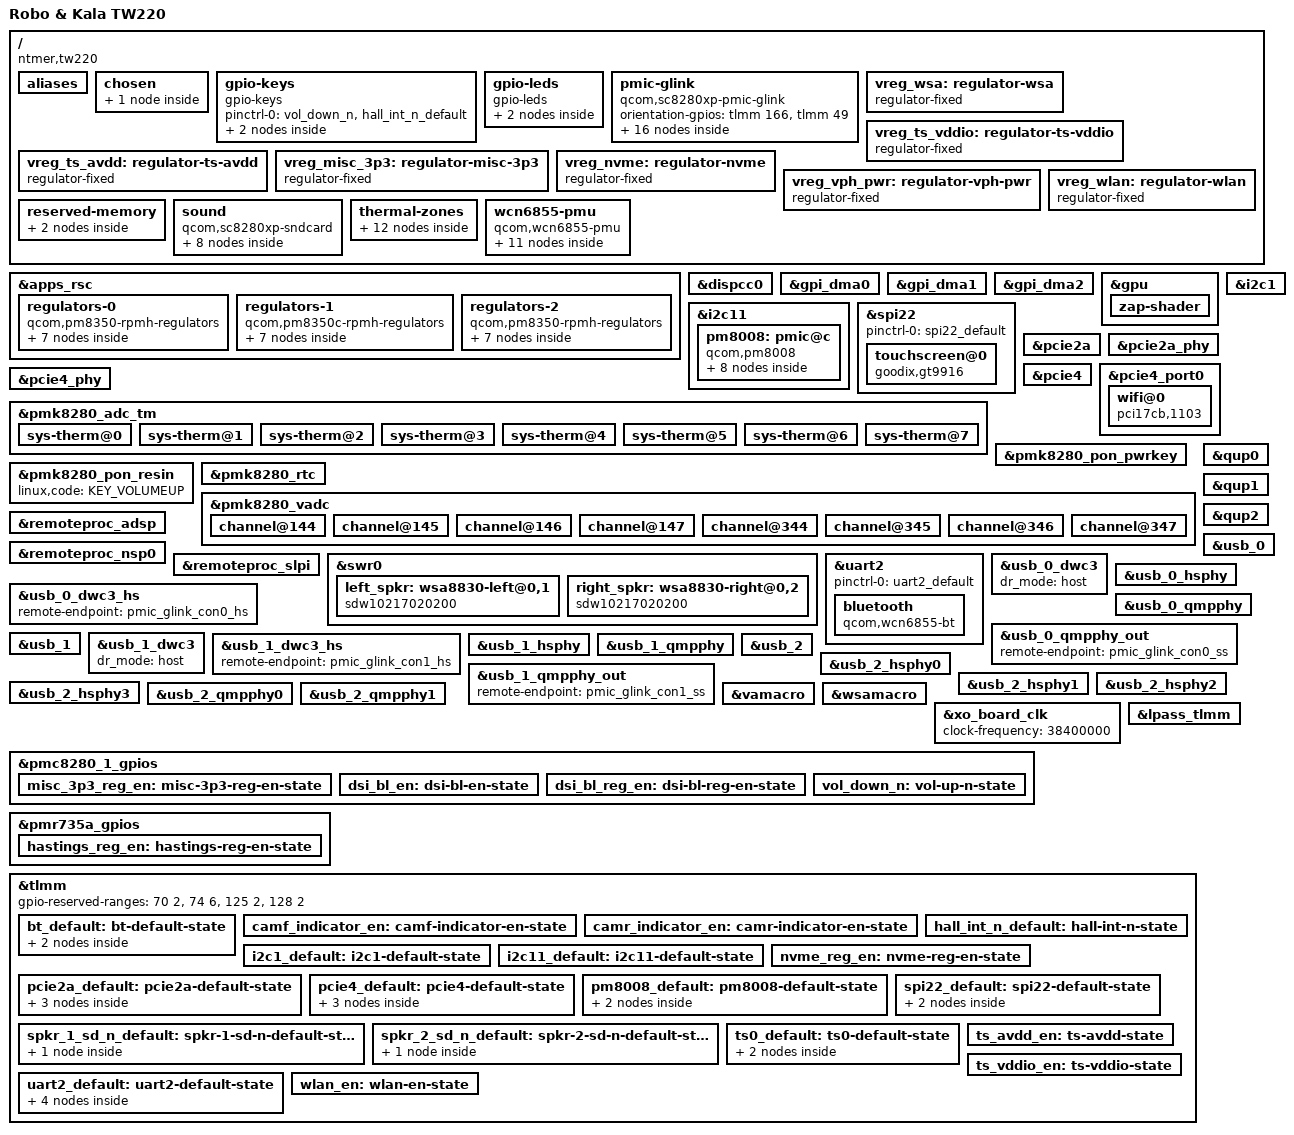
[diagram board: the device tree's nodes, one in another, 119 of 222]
// SPDX-License-Identifier: BSD-3-Clause
/*
 * Copyright (c) 2021, The Linux Foundation. All rights reserved.
 * Copyright (c) 2022, Linaro Limited
 *
 * Copyright (c) 2025, Hong Zhu <vanyang.smail.nju.edu.cn>
 * Copyright (c) 2025, Pengyu Luo <mitltlatltl@gmail.com>
 */

/dts-v1/;

#include <dt-bindings/gpio/gpio.h>
#include <dt-bindings/iio/qcom,spmi-adc7-pm8350.h>
#include <dt-bindings/input/gpio-keys.h>
#include <dt-bindings/input/input.h>
#include <dt-bindings/leds/common.h>
#include <dt-bindings/regulator/qcom,rpmh-regulator.h>
#include <dt-bindings/phy/phy.h>

#include "sc8280xp.dtsi"
#include "sc8280xp-pmics.dtsi"

/ {
	model = "Robo & Kala TW220";
	compatible = "ntmer,tw220", "qcom,sc8280xp";
	chassis-type = "tablet";

	aliases {
		serial0 = &uart2;
		i2c1 = &i2c1;
	};

	chosen {
		#address-cells = <2>;
		#size-cells = <2>;
		ranges;

		framebuffer0: framebuffer@c6200000 {
			compatible = "simple-framebuffer";
			reg = <0x0 0xc6200000 0x0 (2560*1600*4)>;
			width = <2560>;
			height = <1600>;
			stride = <(2560 * 4)>;
			format = "a8r8g8b8";
			clocks = <&dispcc0 DISP_CC_MDSS_MDP_CLK>;
		};
	};

	gpio-keys {
		compatible = "gpio-keys";

		pinctrl-0 = <&vol_down_n>, <&hall_int_n_default>;
		pinctrl-names = "default";

		key-vol-down {
			label = "Volume Down";
			gpios = <&pmc8280_1_gpios 6 GPIO_ACTIVE_LOW>;
			linux,code = <KEY_VOLUMEDOWN>;
			debounce-interval = <15>;
			linux,can-disable;
			wakeup-source;
		};

		switch-lid {
			label = "Lid Switch";
			gpios = <&tlmm 107 GPIO_ACTIVE_LOW>;
			linux,input-type = <EV_SW>;
			linux,code = <SW_LID>;
			wakeup-source;
			wakeup-event-action = <EV_ACT_DEASSERTED>;
		};
	};

	gpio-leds {
		compatible = "gpio-leds";

		pinctrl-names = "default";
		pinctrl-0 = <&camf_indicator_en>, <&camr_indicator_en>;

		flash_camf: led-front-camera-indicator {
			label = "white:front-camera-indicator";
			function = LED_FUNCTION_INDICATOR;
			color = <LED_COLOR_ID_WHITE>;
			gpios = <&tlmm 44 GPIO_ACTIVE_HIGH>;
			linux,default-trigger = "none";
			default-state = "off";
			/* Reuse as a panic indicator until we get a "camera on" trigger */
			panic-indicator;
		};

		flash_camr: led-rear-camera-indicator {
			label = "white:rear-camera-indicator";
			function = LED_FUNCTION_INDICATOR;
			color = <LED_COLOR_ID_WHITE>;
			gpios = <&tlmm 43 GPIO_ACTIVE_HIGH>;
			linux,default-trigger = "none";
			default-state = "off";
			/* Reuse as a panic indicator until we get a "camera on" trigger */
			panic-indicator;
		};
	};

	pmic-glink {
		compatible = "qcom,sc8280xp-pmic-glink", "qcom,pmic-glink";

		#address-cells = <1>;
		#size-cells = <0>;
		orientation-gpios = <&tlmm 166 GPIO_ACTIVE_HIGH>,
				    <&tlmm 49 GPIO_ACTIVE_HIGH>;

		connector@0 {
			compatible = "usb-c-connector";
			reg = <0>;
			power-role = "dual";
			data-role = "dual";

			ports {
				#address-cells = <1>;
				#size-cells = <0>;

				port@0 {
					reg = <0>;

					pmic_glink_con0_hs: endpoint {
						remote-endpoint = <&usb_0_dwc3_hs>;
					};
				};

				port@1 {
					reg = <1>;

					pmic_glink_con0_ss: endpoint {
						remote-endpoint = <&usb_0_qmpphy_out>;
					};
				};

				port@2 {
					reg = <2>;

					pmic_glink_con0_sbu: endpoint {
					};
				};
			};
		};

		connector@1 {
			compatible = "usb-c-connector";
			reg = <1>;
			power-role = "dual";
			data-role = "dual";

			ports {
				#address-cells = <1>;
				#size-cells = <0>;
				port@0 {
					reg = <0>;

					pmic_glink_con1_hs: endpoint {
						remote-endpoint = <&usb_1_dwc3_hs>;
					};
				};

				port@1 {
					reg = <1>;

					pmic_glink_con1_ss: endpoint {
						remote-endpoint = <&usb_1_qmpphy_out>;
					};
				};

				port@2 {
					reg = <2>;

					pmic_glink_con1_sbu: endpoint {
					};
				};
			};
		};
	};

	vreg_wsa: regulator-wsa {
		compatible = "regulator-fixed";

		regulator-name = "vreg_wsa";
		gpio = <&tlmm 28 GPIO_ACTIVE_HIGH>;
		regulator-min-microvolt = <3600000>;
		regulator-max-microvolt = <3600000>;
		enable-active-high;

		regulator-always-on;
		regulator-boot-on;
	};

	vreg_ts_vddio: regulator-ts-vddio {
		compatible = "regulator-fixed";

		regulator-name = "vreg_ts_vddio";
		regulator-min-microvolt = <1800000>;
		regulator-max-microvolt = <1800000>;

		gpio = <&tlmm 90 GPIO_ACTIVE_HIGH>;
		enable-active-high;

		pinctrl-0 = <&ts_vddio_en>;
		pinctrl-names = "default";
	};

	vreg_ts_avdd: regulator-ts-avdd {
		compatible = "regulator-fixed";

		regulator-name = "vreg_ts_avdd";
		regulator-min-microvolt = <3300000>;
		regulator-max-microvolt = <3300000>;

		gpio = <&tlmm 56 GPIO_ACTIVE_HIGH>;
		enable-active-high;

		pinctrl-0 = <&ts_avdd_en>;
		pinctrl-names = "default";
	};

	vreg_misc_3p3: regulator-misc-3p3 {
		compatible = "regulator-fixed";

		regulator-name = "VCC3B";
		regulator-min-microvolt = <3300000>;
		regulator-max-microvolt = <3300000>;

		gpio = <&pmc8280_1_gpios 1 GPIO_ACTIVE_HIGH>;
		enable-active-high;

		pinctrl-0 = <&misc_3p3_reg_en>;
		pinctrl-names = "default";

		regulator-boot-on;
		regulator-always-on;
	};

	vreg_nvme: regulator-nvme {
		compatible = "regulator-fixed";

		regulator-name = "VCC3_SSD";
		regulator-min-microvolt = <3300000>;
		regulator-max-microvolt = <3300000>;

		gpio = <&tlmm 135 GPIO_ACTIVE_HIGH>;
		enable-active-high;

		pinctrl-0 = <&nvme_reg_en>;
		pinctrl-names = "default";

		regulator-boot-on;
	};

	vreg_vph_pwr: regulator-vph-pwr {
		compatible = "regulator-fixed";

		regulator-name = "VPH_VCC3R9";
		regulator-min-microvolt = <3900000>;
		regulator-max-microvolt = <3900000>;

		regulator-always-on;
	};

	vreg_wlan: regulator-wlan {
		compatible = "regulator-fixed";

		regulator-name = "VCC_WLAN_3R9";
		regulator-min-microvolt = <3900000>;
		regulator-max-microvolt = <3900000>;

		gpio = <&pmr735a_gpios 1 GPIO_ACTIVE_HIGH>;
		enable-active-high;

		pinctrl-0 = <&hastings_reg_en>;
		pinctrl-names = "default";

		regulator-boot-on;
	};

	reserved-memory {
		gpu_mem: gpu-mem@8bf00000 {
			reg = <0 0x8bf00000 0 0x2000>;
			no-map;
		};

		linux,cma {
			compatible = "shared-dma-pool";
			size = <0x0 0x8000000>;
			reusable;
			linux,cma-default;
		};
	};

	sound {
		compatible = "qcom,sc8280xp-sndcard";
		model = "SC8280XP-NTMER-TW220";
		audio-routing = "SpkrLeft IN", "WSA_SPK1 OUT",
				"SpkrRight IN", "WSA_SPK2 OUT";

		wsa-dai-link {
			link-name = "WSA Playback";

			cpu {
				sound-dai = <&q6apmbedai WSA_CODEC_DMA_RX_0>;
			};

			codec {
				sound-dai = <&left_spkr>, <&right_spkr>, <&swr0 0>, <&wsamacro 0>;
			};

			platform {
				sound-dai = <&q6apm>;
			};
		};

		va-dai-link {
			link-name = "VA Capture";
			cpu {
				sound-dai = <&q6apmbedai VA_CODEC_DMA_TX_0>;
			};

			codec {
				sound-dai = <&vamacro 0>;
			};

			platform {
				sound-dai = <&q6apm>;
			};
		};
	};

	thermal-zones {
		pm8008-thermal {
			polling-delay-passive = <100>;
			polling-delay = <0>;

			thermal-sensors = <&pm8008>;

			trips {
				trip0 {
					temperature = <95000>;
					hysteresis = <0>;
					type = "passive";
				};

				trip1 {
					temperature = <115000>;
					hysteresis = <0>;
					type = "critical";
				};
			};
		};

		skin-temp-thermal {
			polling-delay-passive = <250>;

			thermal-sensors = <&pmk8280_adc_tm 5>;

			trips {
				skin_temp_alert0: trip-point0 {
					temperature = <55000>;
					hysteresis = <1000>;
					type = "passive";
				};

				skin_temp_alert1: trip-point1 {
					temperature = <58000>;
					hysteresis = <1000>;
					type = "passive";
				};

				skin-temp-crit {
					temperature = <73000>;
					hysteresis = <1000>;
					type = "critical";
				};
			};

			cooling-maps {
				map0 {
					trip = <&skin_temp_alert0>;
					cooling-device = <&cpu4 THERMAL_NO_LIMIT THERMAL_NO_LIMIT>,
					<&cpu5 THERMAL_NO_LIMIT THERMAL_NO_LIMIT>,
					<&cpu6 THERMAL_NO_LIMIT THERMAL_NO_LIMIT>,
					<&cpu7 THERMAL_NO_LIMIT THERMAL_NO_LIMIT>;
				};

				map1 {
					trip = <&skin_temp_alert1>;
					cooling-device = <&cpu4 THERMAL_NO_LIMIT THERMAL_NO_LIMIT>,
					<&cpu5 THERMAL_NO_LIMIT THERMAL_NO_LIMIT>,
					<&cpu6 THERMAL_NO_LIMIT THERMAL_NO_LIMIT>,
					<&cpu7 THERMAL_NO_LIMIT THERMAL_NO_LIMIT>;
				};
			};
		};
	};

	wcn6855-pmu {
		compatible = "qcom,wcn6855-pmu";

		pinctrl-names = "default";
		pinctrl-0 = <&bt_default>, <&wlan_en>;

		wlan-enable-gpios = <&tlmm 134 GPIO_ACTIVE_HIGH>;
		bt-enable-gpios = <&tlmm 133 GPIO_ACTIVE_HIGH>;
		swctrl-gpios = <&tlmm 132 GPIO_ACTIVE_HIGH>;

		vddio-supply = <&vreg_s10b>;
		vddaon-supply = <&vreg_s12b>;
		vddpmu-supply = <&vreg_s12b>;
		vddpmumx-supply = <&vreg_s12b>;
		vddpmucx-supply = <&vreg_s12b>;
		vddrfa0p95-supply = <&vreg_s12b>;
		vddrfa1p3-supply = <&vreg_s11b>;
		vddrfa1p9-supply = <&vreg_s1c>;
		vddpcie1p3-supply = <&vreg_s11b>;
		vddpcie1p9-supply = <&vreg_s1c>;

		regulators {
			vreg_pmu_rfa_cmn_0p8: ldo0 {
				regulator-name = "vreg_pmu_rfa_cmn_0p8";
			};

			vreg_pmu_aon_0p8: ldo1 {
				regulator-name = "vreg_pmu_aon_0p8";
			};

			vreg_pmu_wlcx_0p8: ldo2 {
				regulator-name = "vreg_pmu_wlcx_0p8";
			};

			vreg_pmu_wlmx_0p8: ldo3 {
				regulator-name = "vreg_pmu_wlmx_0p8";
			};

			vreg_pmu_btcmx_0p8: ldo4 {
				regulator-name = "vreg_pmu_btcmx_0p8";
			};

			vreg_pmu_pcie_1p8: ldo5 {
				regulator-name = "vreg_pmu_pcie_1p8";
			};

			vreg_pmu_pcie_0p9: ldo6 {
				regulator-name = "vreg_pmu_pcie_0p9";
			};

			vreg_pmu_rfa_0p8: ldo7 {
				regulator-name = "vreg_pmu_rfa_0p8";
			};

			vreg_pmu_rfa_1p2: ldo8 {
				regulator-name = "vreg_pmu_rfa_1p2";
			};

			vreg_pmu_rfa_1p7: ldo9 {
				regulator-name = "vreg_pmu_rfa_1p7";
			};
		};
	};
};

&apps_rsc {
	regulators-0 {
		compatible = "qcom,pm8350-rpmh-regulators";
		qcom,pmic-id = "b";

		vdd-l1-l4-supply = <&vreg_s12b>;
		vdd-l2-l7-supply = <&vreg_bob>;
		vdd-l3-l5-supply = <&vreg_s11b>;
		vdd-l6-l9-l10-supply = <&vreg_s12b>;
		vdd-l8-supply = <&vreg_s12b>;

		vreg_s10b: smps10 {
			regulator-name = "vreg_s10b";
			regulator-min-microvolt = <1800000>;
			regulator-max-microvolt = <1800000>;
			regulator-initial-mode = <RPMH_REGULATOR_MODE_HPM>;
			regulator-always-on;
		};

		vreg_s11b: smps11 {
			regulator-name = "vreg_s11b";
			regulator-min-microvolt = <1272000>;
			regulator-max-microvolt = <1272000>;
			regulator-initial-mode = <RPMH_REGULATOR_MODE_HPM>;
		};

		vreg_s12b: smps12 {
			regulator-name = "vreg_s12b";
			regulator-min-microvolt = <984000>;
			regulator-max-microvolt = <984000>;
			regulator-initial-mode = <RPMH_REGULATOR_MODE_HPM>;
		};

		vreg_l1b: ldo1 {
			regulator-name = "vreg_l1b";
			regulator-min-microvolt = <912000>;
			regulator-max-microvolt = <912000>;
			regulator-initial-mode = <RPMH_REGULATOR_MODE_HPM>;
			regulator-allow-set-load;
			regulator-allowed-modes = <RPMH_REGULATOR_MODE_LPM
			RPMH_REGULATOR_MODE_HPM>;
		};

		vreg_l3b: ldo3 {
			regulator-name = "vreg_l3b";
			regulator-min-microvolt = <1200000>;
			regulator-max-microvolt = <1200000>;
			regulator-initial-mode = <RPMH_REGULATOR_MODE_HPM>;
			regulator-boot-on;
		};

		vreg_l4b: ldo4 {
			regulator-name = "vreg_l4b";
			regulator-min-microvolt = <912000>;
			regulator-max-microvolt = <912000>;
			regulator-initial-mode = <RPMH_REGULATOR_MODE_HPM>;
			regulator-allow-set-load;
			regulator-allowed-modes = <RPMH_REGULATOR_MODE_LPM
			RPMH_REGULATOR_MODE_HPM>;
		};

		vreg_l6b: ldo6 {
			regulator-name = "vreg_l6b";
			regulator-min-microvolt = <880000>;
			regulator-max-microvolt = <880000>;
			regulator-initial-mode = <RPMH_REGULATOR_MODE_HPM>;
			regulator-boot-on;
		};
	};

	regulators-1 {
		compatible = "qcom,pm8350c-rpmh-regulators";
		qcom,pmic-id = "c";

		vdd-bob-supply = <&vreg_vph_pwr>;
		vdd-l1-l12-supply = <&vreg_s1c>;
		vdd-l2-l8-supply = <&vreg_s1c>;
		vdd-l3-l4-l5-l7-l13-supply = <&vreg_bob>;
		vdd-l6-l9-l11-supply = <&vreg_bob>;
		vdd-l10-supply = <&vreg_s11b>;

		vreg_s1c: smps1 {
			regulator-name = "vreg_s1c";
			regulator-min-microvolt = <1880000>;
			regulator-max-microvolt = <1900000>;
			regulator-initial-mode = <RPMH_REGULATOR_MODE_HPM>;
			regulator-always-on;
		};

		vreg_l1c: ldo1 {
			regulator-name = "vreg_l1c";
			regulator-min-microvolt = <1800000>;
			regulator-max-microvolt = <1800000>;
			regulator-initial-mode = <RPMH_REGULATOR_MODE_HPM>;
			regulator-allow-set-load;
			regulator-allowed-modes = <RPMH_REGULATOR_MODE_LPM
						   RPMH_REGULATOR_MODE_HPM>;
		};

		vreg_l2c: ldo2 {
			regulator-name = "vreg_l2c";
			regulator-min-microvolt = <1800000>;
			regulator-max-microvolt = <1800000>;
			regulator-initial-mode = <RPMH_REGULATOR_MODE_HPM>;
			regulator-allow-set-load;
			regulator-allowed-modes = <RPMH_REGULATOR_MODE_HPM>;
			regulator-always-on;
			regulator-boot-on;
		};

		vreg_l8c: ldo8 {
			regulator-name = "vreg_l8c";
			regulator-min-microvolt = <1800000>;
			regulator-max-microvolt = <1800000>;
			regulator-initial-mode = <RPMH_REGULATOR_MODE_HPM>;
			regulator-allow-set-load;
			regulator-allowed-modes = <RPMH_REGULATOR_MODE_LPM
						   RPMH_REGULATOR_MODE_HPM>;
		};

		vreg_l12c: ldo12 {
			regulator-name = "vreg_l12c";
			regulator-min-microvolt = <1800000>;
			regulator-max-microvolt = <1800000>;
			regulator-initial-mode = <RPMH_REGULATOR_MODE_HPM>;
		};

		vreg_l13c: ldo13 {
			regulator-name = "vreg_l13c";
			regulator-min-microvolt = <3072000>;
			regulator-max-microvolt = <3072000>;
			regulator-initial-mode = <RPMH_REGULATOR_MODE_HPM>;
			regulator-allow-set-load;
			regulator-allowed-modes = <RPMH_REGULATOR_MODE_LPM
						   RPMH_REGULATOR_MODE_HPM>;
		};

		vreg_bob: bob {
			regulator-name = "vreg_bob";
			regulator-min-microvolt = <3008000>;
			regulator-max-microvolt = <3960000>;
			regulator-initial-mode = <RPMH_REGULATOR_MODE_AUTO>;
			regulator-always-on;
		};
	};

	regulators-2 {
		compatible = "qcom,pm8350-rpmh-regulators";
		qcom,pmic-id = "d";

		vdd-l1-l4-supply = <&vreg_s11b>;
		vdd-l2-l7-supply = <&vreg_bob>;
		vdd-l3-l5-supply = <&vreg_s11b>;
		vdd-l6-l9-l10-supply = <&vreg_s12b>;
		vdd-l8-supply = <&vreg_s12b>;

		vreg_l2d: ldo2 {
			regulator-name = "vreg_l2d";
			regulator-min-microvolt = <3072000>;
			regulator-max-microvolt = <3072000>;
			regulator-initial-mode = <RPMH_REGULATOR_MODE_HPM>;
			regulator-allow-set-load;
			regulator-allowed-modes = <RPMH_REGULATOR_MODE_LPM
						   RPMH_REGULATOR_MODE_HPM>;
		};

		vreg_l4d: ldo4 {
			regulator-name = "vreg_l4d";
			regulator-min-microvolt = <1200000>;
			regulator-max-microvolt = <1200000>;
			regulator-initial-mode = <RPMH_REGULATOR_MODE_HPM>;
			regulator-allow-set-load;
			regulator-allowed-modes = <RPMH_REGULATOR_MODE_LPM
						   RPMH_REGULATOR_MODE_HPM>;
		};

		vreg_l6d: ldo6 {
			regulator-name = "vreg_l6d";
			regulator-min-microvolt = <880000>;
			regulator-max-microvolt = <880000>;
			regulator-initial-mode = <RPMH_REGULATOR_MODE_HPM>;
			regulator-allow-set-load;
			regulator-allowed-modes = <RPMH_REGULATOR_MODE_LPM
						   RPMH_REGULATOR_MODE_HPM>;
		};

		vreg_l7d: ldo7 {
			regulator-name = "vreg_l7d";
			regulator-min-microvolt = <3072000>;
			regulator-max-microvolt = <3072000>;
			regulator-initial-mode = <RPMH_REGULATOR_MODE_HPM>;
			regulator-allow-set-load;
			regulator-allowed-modes = <RPMH_REGULATOR_MODE_LPM
						   RPMH_REGULATOR_MODE_HPM>;
		};

		vreg_l8d: ldo8 {
			regulator-name = "vreg_l8d";
			regulator-min-microvolt = <912000>;
			regulator-max-microvolt = <912000>;
			regulator-initial-mode = <RPMH_REGULATOR_MODE_HPM>;
			regulator-allow-set-load;
			regulator-allowed-modes = <RPMH_REGULATOR_MODE_LPM
						   RPMH_REGULATOR_MODE_HPM>;
		};

		vreg_l9d: ldo9 {
			regulator-name = "vreg_l9d";
			regulator-min-microvolt = <912000>;
			regulator-max-microvolt = <912000>;
			regulator-initial-mode = <RPMH_REGULATOR_MODE_HPM>;
			regulator-allow-set-load;
			regulator-allowed-modes = <RPMH_REGULATOR_MODE_LPM
						   RPMH_REGULATOR_MODE_HPM>;
		};

		vreg_l10d: ldo10 {
			regulator-name = "vreg_l10d";
			regulator-min-microvolt = <912000>;
			regulator-max-microvolt = <912000>;
			regulator-initial-mode = <RPMH_REGULATOR_MODE_HPM>;
			regulator-allow-set-load;
			regulator-boot-on;
			regulator-always-on;
			regulator-allowed-modes = <RPMH_REGULATOR_MODE_LPM
						   RPMH_REGULATOR_MODE_HPM>;
		};
	};
};

/*
 * cci0_i2c1
 * sda: gpio115, scl: gpio116
 *
 * CAMI ov9234 @36 @48
 *
 * power on sequence
 * gpio7 out low
 * l3q 1p8
 * l6q 2p8
 * l2q 1p2
 * gpio7 out high
 * msleep 5
 * cam_cc_mclk4_clk 2.4MHz (gpio6)
 */

/*
 * cci2_i2c1
 * sda: gpio12, scl: gpio13
 *
 * CAMF gc5035 @37
 *
 * power on sequence
 * gpio15 out low
 * l3q 1p8
 * msleep 1
 * l2q 1p2
 * msleep 1
 * l5q 2p8
 * gpio15 out high
 * gpio67 out high
 * msleep 10
 * cam_cc_mclk3_clk 2.4MHz (gpio17)
 */

/*
 * cci1_i2c0
 * sda: gpio10, scl: gpio11
 *
 * CAMR ov13b10 @0c
 *
 * power on sequence
 * gpio66 out low
 * l1q 1p2
 * l7q 2p8
 * l3q 1p8
 * gpio59 out high
 * gpio66 out high
 * msleep 5
 * cam_cc_mclk2_clk 2.4MHz (gpio16/gpio119/gpio120?)
 */

&dispcc0 {
	status = "okay";
};

&gpi_dma0 {
	status = "okay";
};

&gpi_dma1 {
	status = "okay";
};

&gpi_dma2 {
	status = "okay";
};

&gpu {
	status = "okay";

	zap-shader {
		memory-region = <&gpu_mem>;
		firmware-name = "qcom/sc8280xp/Ntmer/tw220/qcdxkmsuc8280.mbn";
	};
};

&i2c1 {
	clock-frequency = <400000>;

	pinctrl-0 = <&i2c1_default>;
	pinctrl-names = "default";

	status = "okay";

	/*
	 * cps4035 @30 @31
	 * gpio73, 87, 154
	 */
};

&i2c11 {
	clock-frequency = <400000>;

	pinctrl-names = "default";
	pinctrl-0 = <&i2c11_default>;

	status = "okay";

	pm8008: pmic@c {
		compatible = "qcom,pm8008";
		reg = <0xc>;

		interrupts-extended = <&tlmm 41 IRQ_TYPE_EDGE_RISING>;
		reset-gpios = <&tlmm 42 GPIO_ACTIVE_LOW>;

		vdd-l1-l2-supply = <&vreg_s11b>;
		vdd-l3-l4-supply = <&vreg_bob>;
		vdd-l5-supply = <&vreg_bob>;
		vdd-l6-supply = <&vreg_bob>;
		vdd-l7-supply = <&vreg_bob>;

		pinctrl-names = "default";
		pinctrl-0 = <&pm8008_default>;

		gpio-controller;
		#gpio-cells = <2>;
		gpio-ranges = <&pm8008 0 0 2>;

		interrupt-controller;
		#interrupt-cells = <2>;

		#thermal-sensor-cells = <0>;

		regulators {
			vreg_l1q: ldo1 {
				regulator-name = "vreg_l1q";
				regulator-min-microvolt = <1200000>;
				regulator-max-microvolt = <1200000>;
			};

			vreg_l2q: ldo2 {
				regulator-name = "vreg_l2q";
				regulator-min-microvolt = <1200000>;
				regulator-max-microvolt = <1200000>;
			};

			vreg_l3q: ldo3 {
				regulator-name = "vreg_l3q";
				regulator-min-microvolt = <1800000>;
				regulator-max-microvolt = <1800000>;
			};

			vreg_l4q: ldo4 {
				regulator-name = "vreg_l4q";
				regulator-min-microvolt = <1800000>;
				regulator-max-microvolt = <1800000>;
			};

			vreg_l5q: ldo5 {
				regulator-name = "vreg_l5q";
				regulator-min-microvolt = <2800000>;
				regulator-max-microvolt = <2800000>;
			};

			vreg_l6q: ldo6 {
				regulator-name = "vreg_l6q";
				regulator-min-microvolt = <2800000>;
				regulator-max-microvolt = <2800000>;
			};

			vreg_l7q: ldo7 {
				regulator-name = "vreg_l7q";
				regulator-min-microvolt = <2800000>;
				regulator-max-microvolt = <2800000>;
			};
		};
	};
};

&spi22 {
	status = "okay";
	pinctrl-0 = <&spi22_default>;
	pinctrl-names = "default";

	touchscreen@0 {
		/*
		 * The ACPI device ID is GXTS7986, its exact suffix is unknown.
		 * The Windows driver suggests it is a GTBerlinB variant and
		 * communicates via HID over SPI, which aligns with the Linux
		 * driver `drivers/hid/hid-goodix-spi.c`.
		 *
		 * However, the HID descriptor read from the device appears
		 * garbled, preventing proper probe with the HID driver. In
		 * contrast, the driver at
		 * `drivers/input/touchscreen/goodix_berlin_spi.c` shares many
		 * similarities and functions correctly with this hardware.
		 *
		 * Therefore, we choose to use the goodix_berlin_spi driver
		 * instead.
		 */
		compatible = "goodix,gt9916";
		reg = <0>;

		interrupts-extended = <&tlmm 175 IRQ_TYPE_LEVEL_LOW>;
		reset-gpios = <&tlmm 99 GPIO_ACTIVE_LOW>;
		vddio-supply = <&vreg_ts_vddio>;
		avdd-supply = <&vreg_ts_avdd>;

		spi-max-frequency = <3000000>;

		touchscreen-size-x = <2560>;
		touchscreen-size-y = <1600>;

		pinctrl-0 = <&ts0_default>;
		pinctrl-names = "default";
	};
};

/*
 * mdss0_dsi display:
 *
 * reset gpio109
 *
 * power on seq:
 * ldo 3b: 1.2v dsi
 * ldo 6b: 0.88v dsi_phy
 *
 * panel:
 * ldo 2b: 1.8v vddio
 * gpio55 out high
 * msleep 15
 * gpio25 out high
 * msleep 5
 *
 * backlight:
 * dsi_bl_reg_en: gpio9
 * msleep 5
 * dsi_bl_en: gpio8
 *
 * power off sequence
 * dis_off:
 * ldo 3b
 * ldo 6b
 * ldo 2b
 *
 * bl_off:
 * dsi_bl_en: gpio8
 * msleep 5
 * dsi_bl_reg_en: gpio9
 * msleep 5
 *
 * panel_off:
 * gpio25: out low
 * msleep 5
 * gpio55: out low
 * msleep 5
 */

&pcie2a {
	perst-gpios = <&tlmm 143 GPIO_ACTIVE_LOW>;
	wake-gpios = <&tlmm 145 GPIO_ACTIVE_LOW>;

	vddpe-3v3-supply = <&vreg_nvme>;

	pinctrl-0 = <&pcie2a_default>;
	pinctrl-names = "default";

	status = "okay";
};

&pcie2a_phy {
	vdda-phy-supply = <&vreg_l6d>;
	vdda-pll-supply = <&vreg_l4d>;

	status = "okay";
};

&pcie4 {
	max-link-speed = <2>;

	perst-gpios = <&tlmm 141 GPIO_ACTIVE_LOW>;
	wake-gpios = <&tlmm 139 GPIO_ACTIVE_LOW>;

	vddpe-3v3-supply = <&vreg_wlan>;

	pinctrl-0 = <&pcie4_default>;
	pinctrl-names = "default";

	status = "okay";
};

&pcie4_port0 {
	wifi@0 {
		compatible = "pci17cb,1103";
		reg = <0x10000 0x0 0x0 0x0 0x0>;

		vddrfacmn-supply = <&vreg_pmu_rfa_cmn_0p8>;
		vddaon-supply = <&vreg_pmu_aon_0p8>;
		vddwlcx-supply = <&vreg_pmu_wlcx_0p8>;
		vddwlmx-supply = <&vreg_pmu_wlmx_0p8>;
		vddpcie1p8-supply = <&vreg_pmu_pcie_1p8>;
		vddpcie0p9-supply = <&vreg_pmu_pcie_0p9>;
		vddrfa0p8-supply = <&vreg_pmu_rfa_0p8>;
		vddrfa1p2-supply = <&vreg_pmu_rfa_1p2>;
		vddrfa1p8-supply = <&vreg_pmu_rfa_1p7>;

		/*
		 * bus=pci,vendor=17cb,device=1103,subsystem-vendor=17cb,
		 * subsystem-device=0108,qmi-chip-id=18,qmi-board-id=255
		 *
		 * Regenerate board file, x13s one works well
		 */
	};
};

&pcie4_phy {
	vdda-phy-supply = <&vreg_l6d>;
	vdda-pll-supply = <&vreg_l4d>;

	status = "okay";
};

&pmk8280_adc_tm {
	status = "okay";

	sys-therm@0 {
		reg = <0>;
		io-channels = <&pmk8280_vadc PM8350_ADC7_AMUX_THM1_100K_PU(1)>;
		qcom,hw-settle-time-us = <200>;
		qcom,avg-samples = <2>;
		qcom,ratiometric;
	};

	sys-therm@1 {
		reg = <1>;
		io-channels = <&pmk8280_vadc PM8350_ADC7_AMUX_THM2_100K_PU(1)>;
		qcom,hw-settle-time-us = <200>;
		qcom,avg-samples = <2>;
		qcom,ratiometric;
	};

	sys-therm@2 {
		reg = <2>;
		io-channels = <&pmk8280_vadc PM8350_ADC7_AMUX_THM3_100K_PU(1)>;
		qcom,hw-settle-time-us = <200>;
		qcom,avg-samples = <2>;
		qcom,ratiometric;
	};

	sys-therm@3 {
		reg = <3>;
		io-channels = <&pmk8280_vadc PM8350_ADC7_AMUX_THM4_100K_PU(1)>;
		qcom,hw-settle-time-us = <200>;
		qcom,avg-samples = <2>;
		qcom,ratiometric;
	};

	sys-therm@4 {
		reg = <4>;
		io-channels = <&pmk8280_vadc PM8350_ADC7_AMUX_THM1_100K_PU(3)>;
		qcom,hw-settle-time-us = <200>;
		qcom,avg-samples = <2>;
		qcom,ratiometric;
	};

	sys-therm@5 {
		reg = <5>;
		io-channels = <&pmk8280_vadc PM8350_ADC7_AMUX_THM2_100K_PU(3)>;
		qcom,hw-settle-time-us = <200>;
		qcom,avg-samples = <2>;
		qcom,ratiometric;
	};

	sys-therm@6 {
		reg = <6>;
		io-channels = <&pmk8280_vadc PM8350_ADC7_AMUX_THM3_100K_PU(3)>;
		qcom,hw-settle-time-us = <200>;
		qcom,avg-samples = <2>;
		qcom,ratiometric;
	};

	sys-therm@7 {
		reg = <7>;
		io-channels = <&pmk8280_vadc PM8350_ADC7_AMUX_THM4_100K_PU(3)>;
		qcom,hw-settle-time-us = <200>;
		qcom,avg-samples = <2>;
		qcom,ratiometric;
	};
};

&pmk8280_pon_pwrkey {
	status = "okay";
};

&pmk8280_pon_resin {
	status = "okay";
	linux,code = <KEY_VOLUMEUP>;
};

&pmk8280_rtc {
	status = "okay";
};

&pmk8280_vadc {
	channel@144 {
		reg = <PM8350_ADC7_AMUX_THM1_100K_PU(1)>;
		qcom,hw-settle-time = <200>;
		qcom,ratiometric;
		label = "sys_therm1";
	};

	channel@145 {
		reg = <PM8350_ADC7_AMUX_THM2_100K_PU(1)>;
		qcom,hw-settle-time = <200>;
		qcom,ratiometric;
		label = "sys_therm2";
	};

	channel@146 {
		reg = <PM8350_ADC7_AMUX_THM3_100K_PU(1)>;
		qcom,hw-settle-time = <200>;
		qcom,ratiometric;
		label = "sys_therm3";
	};

	channel@147 {
		reg = <PM8350_ADC7_AMUX_THM4_100K_PU(1)>;
		qcom,hw-settle-time = <200>;
		qcom,ratiometric;
		label = "sys_therm4";
	};

	channel@344 {
		reg = <PM8350_ADC7_AMUX_THM1_100K_PU(3)>;
		qcom,hw-settle-time = <200>;
		qcom,ratiometric;
		label = "sys_therm5";
	};

	channel@345 {
		reg = <PM8350_ADC7_AMUX_THM2_100K_PU(3)>;
		qcom,hw-settle-time = <200>;
		qcom,ratiometric;
		label = "sys_therm6";
	};

	channel@346 {
		reg = <PM8350_ADC7_AMUX_THM3_100K_PU(3)>;
		qcom,hw-settle-time = <200>;
		qcom,ratiometric;
		label = "sys_therm7";
	};

	channel@347 {
		reg = <PM8350_ADC7_AMUX_THM4_100K_PU(3)>;
		qcom,hw-settle-time = <200>;
		qcom,ratiometric;
		label = "sys_therm8";
	};
};

&qup0 {
	status = "okay";
};

&qup1 {
	status = "okay";
};

&qup2 {
	status = "okay";
};

&remoteproc_adsp {
	firmware-name = "qcom/sc8280xp/Ntmer/tw220/qcadsp8280.mbn";

	status = "okay";
};

&remoteproc_nsp0 {
	firmware-name = "qcom/sc8280xp/Ntmer/tw220/qccdsp8280.mbn";

	status = "okay";
};

&remoteproc_slpi {
	firmware-name = "qcom/sc8280xp/Ntmer/tw220/qcslpi8280.mbn";
	status = "okay";
};

&swr0 {
	status = "okay";

	left_spkr: wsa8830-left@0,1 {
		compatible = "sdw10217020200";
		reg = <0 1>;
		pinctrl-0 = <&spkr_1_sd_n_default>;
		pinctrl-names = "default";
		powerdown-gpios = <&tlmm 178 GPIO_ACTIVE_LOW>;
		#thermal-sensor-cells = <0>;
		sound-name-prefix = "SpkrLeft";
		#sound-dai-cells = <0>;
		vdd-supply = <&vreg_s10b>;
	};

	right_spkr: wsa8830-right@0,2 {
		compatible = "sdw10217020200";
		reg = <0 2>;
		pinctrl-0 = <&spkr_2_sd_n_default>;
		pinctrl-names = "default";
		powerdown-gpios = <&tlmm 179 GPIO_ACTIVE_LOW>;
		#thermal-sensor-cells = <0>;
		sound-name-prefix = "SpkrRight";
		#sound-dai-cells = <0>;
		vdd-supply = <&vreg_s10b>;
	};
};

&uart2 {
	pinctrl-0 = <&uart2_default>;
	pinctrl-names = "default";

	status = "okay";

	bluetooth {
		compatible = "qcom,wcn6855-bt";

		vddrfacmn-supply = <&vreg_pmu_rfa_cmn_0p8>;
		vddaon-supply = <&vreg_pmu_aon_0p8>;
		vddwlcx-supply = <&vreg_pmu_wlcx_0p8>;
		vddwlmx-supply = <&vreg_pmu_wlmx_0p8>;
		vddbtcmx-supply = <&vreg_pmu_btcmx_0p8>;
		vddrfa0p8-supply = <&vreg_pmu_rfa_0p8>;
		vddrfa1p2-supply = <&vreg_pmu_rfa_1p2>;
		vddrfa1p8-supply = <&vreg_pmu_rfa_1p7>;

		local-bd-address = [ 00 11 22 33 44 55 ];
		max-speed = <3200000>;
	};
};

&usb_0 {
	status = "okay";
};

&usb_0_dwc3 {
	dr_mode = "host";
};

&usb_0_dwc3_hs {
	remote-endpoint = <&pmic_glink_con0_hs>;
};

&usb_0_hsphy {
	vdda-pll-supply = <&vreg_l6d>;
	vdda18-supply = <&vreg_l1c>;
	vdda33-supply = <&vreg_l7d>;

	status = "okay";
};

&usb_0_qmpphy {
	vdda-phy-supply = <&vreg_l4d>;
	vdda-pll-supply = <&vreg_l9d>;

	orientation-switch;

	status = "okay";
};

&usb_0_qmpphy_out {
	remote-endpoint = <&pmic_glink_con0_ss>;
};

&usb_1 {
	status = "okay";
};

&usb_1_dwc3 {
	dr_mode = "host";
};

&usb_1_dwc3_hs {
	remote-endpoint = <&pmic_glink_con1_hs>;
};

&usb_1_hsphy {
	vdda-pll-supply = <&vreg_l6b>;
	vdda18-supply = <&vreg_l1c>;
	vdda33-supply = <&vreg_l13c>;

	status = "okay";
};

&usb_1_qmpphy {
	vdda-phy-supply = <&vreg_l3b>;
	vdda-pll-supply = <&vreg_l4b>;

	orientation-switch;

	status = "okay";
};

&usb_1_qmpphy_out {
	remote-endpoint = <&pmic_glink_con1_ss>;
};

&usb_2 {
	status = "okay";
};

&usb_2_hsphy0 {
	vdda-pll-supply = <&vreg_l6d>;
	vdda18-supply = <&vreg_l1c>;
	vdda33-supply = <&vreg_l7d>;

	status = "okay";
};

&usb_2_hsphy1 {
	vdda-pll-supply = <&vreg_l6d>;
	vdda18-supply = <&vreg_l1c>;
	vdda33-supply = <&vreg_l7d>;

	status = "okay";
};

&usb_2_hsphy2 {
	vdda-pll-supply = <&vreg_l6d>;
	vdda18-supply = <&vreg_l8c>;
	vdda33-supply = <&vreg_l2d>;

	status = "okay";
};

&usb_2_hsphy3 {
	vdda-pll-supply = <&vreg_l6d>;
	vdda18-supply = <&vreg_l8c>;
	vdda33-supply = <&vreg_l2d>;

	status = "okay";
};

&usb_2_qmpphy0 {
	vdda-phy-supply = <&vreg_l4d>;
	vdda-pll-supply = <&vreg_l1b>;

	status = "okay";
};

&usb_2_qmpphy1 {
	vdda-phy-supply = <&vreg_l4d>;
	vdda-pll-supply = <&vreg_l8d>;

	status = "okay";
};

&vamacro {
	pinctrl-0 = <&dmic01_default>, <&dmic23_default>;
	pinctrl-names = "default";

	vdd-micb-supply = <&vreg_s10b>;

	qcom,dmic-sample-rate = <4800000>;

	status = "okay";
};

&wsamacro {
	status = "okay";
};

&xo_board_clk {
	clock-frequency = <38400000>;
};

/* PINCTRL */

&lpass_tlmm {
	status = "okay";
};

&pmc8280_1_gpios {
	misc_3p3_reg_en: misc-3p3-reg-en-state {
		pins = "gpio1";
		function = "normal";
	};

	dsi_bl_en: dsi-bl-en-state {
		pins = "gpio8";
		function = "normal";
	};

	dsi_bl_reg_en: dsi-bl-reg-en-state {
		pins = "gpio9";
		function = "normal";
	};

	vol_down_n: vol-up-n-state {
		pins = "gpio6";
		function = "normal";
		power-source = <1>;
		input-enable;
		bias-pull-up;
	};
};

&pmr735a_gpios {
	hastings_reg_en: hastings-reg-en-state {
		pins = "gpio1";
		function = "normal";
	};
};

&tlmm {
	gpio-reserved-ranges = <70 2>, <74 6>, <125 2>, <128 2>;

	bt_default: bt-default-state {
		hstp-bt-en-pins {
			pins = "gpio133";
			function = "gpio";
			drive-strength = <16>;
			bias-disable;
		};

		hstp-sw-ctrl-pins {
			pins = "gpio132";
			function = "gpio";
			bias-pull-down;
		};
	};

	camf_indicator_en: camf-indicator-en-state {
		pins = "gpio44";
		function = "gpio";
		drive-strength = <2>;
		bias-disable;
	};

	camr_indicator_en: camr-indicator-en-state {
		pins = "gpio43";
		function = "gpio";
		drive-strength = <2>;
		bias-disable;
	};

	hall_int_n_default: hall-int-n-state {
		pins = "gpio107";
		function = "gpio";
		bias-disable;
	};

	i2c1_default: i2c1-default-state {
		pins = "gpio158", "gpio159";
		function = "qup1";
		drive-strength = <2>;
		bias-pull-up;
	};

	i2c11_default: i2c11-default-state {
		pins = "gpio18", "gpio19";
		function = "qup11";
		drive-strength = <2>;
		bias-pull-up;
	};

	nvme_reg_en: nvme-reg-en-state {
		pins = "gpio135";
		function = "gpio";
		drive-strength = <2>;
		bias-disable;
	};

	pcie2a_default: pcie2a-default-state {
		clkreq-n-pins {
			pins = "gpio142";
			function = "pcie2a_clkreq";
			drive-strength = <2>;
			bias-pull-up;
		};

		perst-n-pins {
			pins = "gpio143";
			function = "gpio";
			drive-strength = <2>;
			bias-disable;
		};

		wake-n-pins {
			pins = "gpio145";
			function = "gpio";
			drive-strength = <2>;
			bias-pull-up;
		};
	};

	pcie4_default: pcie4-default-state {
		clkreq-n-pins {
			pins = "gpio140";
			function = "pcie4_clkreq";
			drive-strength = <2>;
			bias-pull-up;
		};

		perst-n-pins {
			pins = "gpio141";
			function = "gpio";
			drive-strength = <2>;
			bias-disable;
		};

		wake-n-pins {
			pins = "gpio139";
			function = "gpio";
			drive-strength = <2>;
			bias-pull-up;
		};
	};

	pm8008_default: pm8008-default-state {
		int-pins {
			pins = "gpio41";
			function = "gpio";
			drive-strength = <2>;
			bias-pull-down;
		};

		reset-n-pins {
			pins = "gpio42";
			function = "gpio";
			drive-strength = <2>;
			bias-disable;
		};
	};

	spi22_default: spi22-default-state {
		cs-pins {
			pins = "gpio86";
			function = "qup22";
			drive-strength = <2>;
			bias-pull-down;
		};

		data-clk-pins {
			/* MISO, MOSI, CLK */
			pins = "gpio83", "gpio84", "gpio85";
			function = "qup22";
			drive-strength = <2>;
			bias-pull-down;
		};
	};

	spkr_1_sd_n_default: spkr-1-sd-n-default-state {
		perst-n-pins {
			pins = "gpio178";
			function = "gpio";
			drive-strength = <16>;
			bias-disable;
			output-high;
		};
	};

	spkr_2_sd_n_default: spkr-2-sd-n-default-state {
		perst-n-pins {
			pins = "gpio179";
			function = "gpio";
			drive-strength = <16>;
			bias-disable;
			output-high;
		};
	};

	ts0_default: ts0-default-state {
		int-n-pins {
			pins = "gpio175";
			function = "gpio";
			drive-strength = <2>;
			bias-pull-up;
		};

		reset-n-pins {
			pins = "gpio99";
			function = "gpio";
			drive-strength = <2>;
			bias-disable;
		};
	};

	ts_avdd_en: ts-avdd-state {
		pins = "gpio56";
		function = "gpio";
		drive-strength = <2>;
		bias-disable;
	};

	ts_vddio_en: ts-vddio-state {
		pins = "gpio90";
		function = "gpio";
		drive-strength = <2>;
		bias-disable;
	};

	uart2_default: uart2-default-state {
		cts-pins {
			pins = "gpio121";
			function = "qup2";
			bias-bus-hold;
		};

		rts-pins {
			pins = "gpio122";
			function = "qup2";
			drive-strength = <2>;
			bias-disable;
		};

		rx-pins {
			pins = "gpio124";
			function = "qup2";
			bias-pull-up;
		};

		tx-pins {
			pins = "gpio123";
			function = "qup2";
			drive-strength = <2>;
			bias-disable;
		};
	};

	wlan_en: wlan-en-state {
		pins = "gpio134";
		function = "gpio";
		drive-strength = <8>;
		bias-pull-down;
	};
};
